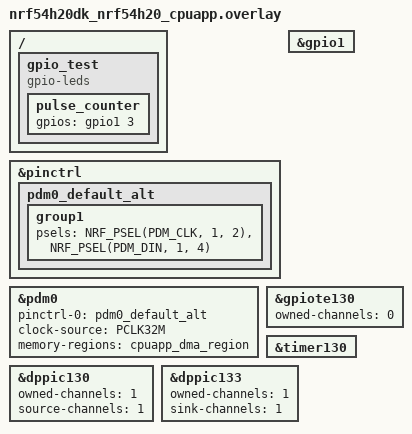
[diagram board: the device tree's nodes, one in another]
/*
 * Copyright (c) 2024 Nordic Semiconductor ASA
 *
 * SPDX-License-Identifier: LicenseRef-Nordic-5-Clause
 */

/ {
	gpio_test {
		compatible = "gpio-leds";

		pulse_counter: pulse_counter {
			gpios = <&gpio1 3 GPIO_ACTIVE_HIGH>;
		};
	};
};

&pinctrl {
	pdm0_default_alt: pdm0_default_alt {
		group1 {
			psels = <NRF_PSEL(PDM_CLK, 1, 2)>,
				<NRF_PSEL(PDM_DIN, 1, 4)>;
		};
	};
};

pdm_dev: &pdm0 {
	status = "okay";
	pinctrl-0 = <&pdm0_default_alt>;
	pinctrl-names = "default";
	clock-source = "PCLK32M";
	memory-regions = <&cpuapp_dma_region>;
};

&gpio1 {
	status = "okay";
};

&gpiote130 {
	owned-channels = <0>;
	status = "okay";
};

&timer130 {
	status = "okay";
};

&dppic130 {
	owned-channels = <1>;
	source-channels = <1>;
	status = "okay";
};

&dppic133 {
	owned-channels = <1>;
	sink-channels = <1>;
	status = "okay";
};
